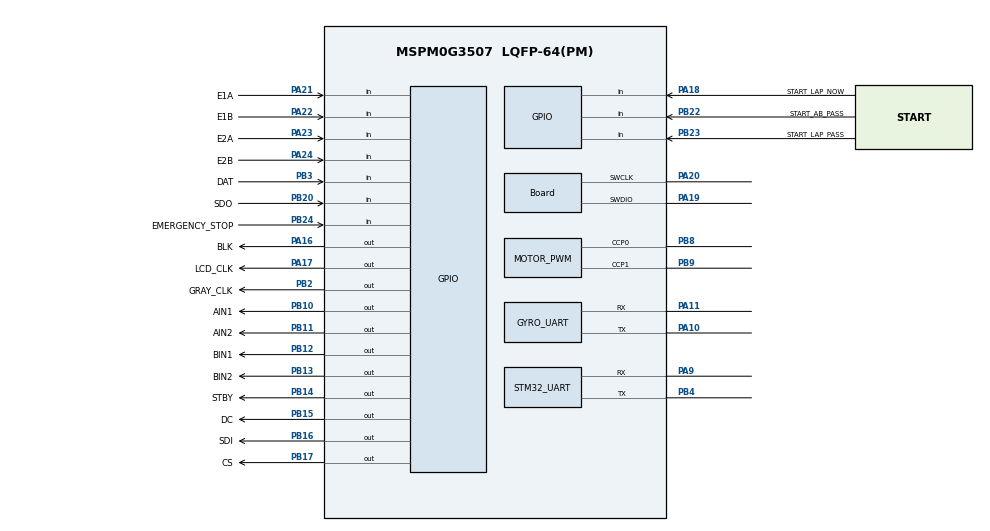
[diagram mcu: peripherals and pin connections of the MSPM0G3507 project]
/**
 * 2026 H题循迹小车 - 全新 MSPM0G3507 引脚配置
 *
 * 说明：
 * 1. 使用 MSPM0G3507 LQFP-64。
 * 2. LCD 严格按照用户给出的六根信号线配置为 GPIO 软件 SPI。
 * 3. 两路电机 PWM 共用 TIMA0，频率一致，上电占空比为 0%。
 * 4. PA19/PA20 固定保留给 SWD 调试。
 */
//@cliArgs --device "MSPM0G350X" --package "LQFP-64(PM)" --part "Default"
//@v2CliArgs --device "MSPM0G3507" --package "LQFP-64(PM)"

const Board   = scripting.addModule("/ti/driverlib/Board");
const GPIO    = scripting.addModule("/ti/driverlib/GPIO", {}, false);
const PWM     = scripting.addModule("/ti/driverlib/PWM", {}, false);
const SYSTICK = scripting.addModule("/ti/driverlib/SYSTICK");
const SYSCTL  = scripting.addModule("/ti/driverlib/SYSCTL");
const UART    = scripting.addModule("/ti/driverlib/UART", {}, false);

const LCD_GPIO       = GPIO.addInstance();
const KEY_GPIO       = GPIO.addInstance();
const MOTOR_CTRL_GPIO = GPIO.addInstance();
const ENCODER_GPIO   = GPIO.addInstance();
const GRAY_GPIO      = GPIO.addInstance();
const MOTOR_PWM      = PWM.addInstance();
const GYRO_UART      = UART.addInstance();
const STM32_UART     = UART.addInstance();

/*
 * 保留 SWD 调试口；不要把 PA19/PA20 分配给业务外设。
 */
Board.configureUnused               = false;
Board.peripheral.$assign            = "DEBUGSS";
Board.peripheral.swdioPin.$assign   = "PA19";
Board.peripheral.swclkPin.$assign   = "PA20";

/*
 * 2.4 寸 LCD：GPIO 软件 SPI。
 * CS 上电保持高，BLK 上电关闭，CLK/SDI/D-C 上电为低。
 */
LCD_GPIO.$name = "LCD_GPIO";
LCD_GPIO.associatedPins.create(6);

LCD_GPIO.associatedPins[0].$name        = "BLK";
LCD_GPIO.associatedPins[0].initialValue = "CLEARED";
LCD_GPIO.associatedPins[0].pin.$assign  = "PA16";

LCD_GPIO.associatedPins[1].$name        = "DC";
LCD_GPIO.associatedPins[1].initialValue = "CLEARED";
LCD_GPIO.associatedPins[1].pin.$assign  = "PB15";

LCD_GPIO.associatedPins[2].$name             = "SDO";
LCD_GPIO.associatedPins[2].direction         = "INPUT";
LCD_GPIO.associatedPins[2].internalResistor  = "PULL_DOWN";
LCD_GPIO.associatedPins[2].pin.$assign       = "PB20";

LCD_GPIO.associatedPins[3].$name        = "CS";
LCD_GPIO.associatedPins[3].initialValue = "SET";
LCD_GPIO.associatedPins[3].pin.$assign  = "PB17";

LCD_GPIO.associatedPins[4].$name        = "LCD_CLK";
LCD_GPIO.associatedPins[4].initialValue = "CLEARED";
LCD_GPIO.associatedPins[4].pin.$assign  = "PA17";

LCD_GPIO.associatedPins[5].$name        = "SDI";
LCD_GPIO.associatedPins[5].initialValue = "CLEARED";
LCD_GPIO.associatedPins[5].pin.$assign  = "PB16";

/*
 * 板载按键：
 * PA18 按下为高电平；PB22/PB23/PB24 按下为低电平。
 * PA18=一圈到线即停，PB22=A到B整车通过，PB23=一圈整车通过，
 * PB24=任意时刻急停。四个按键都启用中断。
 */
KEY_GPIO.$name = "KEY_GPIO";
KEY_GPIO.associatedPins.create(4);

KEY_GPIO.associatedPins[0].$name             = "START_LAP_NOW";
KEY_GPIO.associatedPins[0].direction         = "INPUT";
KEY_GPIO.associatedPins[0].internalResistor  = "PULL_DOWN";
KEY_GPIO.associatedPins[0].interruptEn       = true;
KEY_GPIO.associatedPins[0].polarity          = "RISE";
KEY_GPIO.associatedPins[0].pin.$assign       = "PA18";

KEY_GPIO.associatedPins[1].$name             = "START_AB_PASS";
KEY_GPIO.associatedPins[1].direction         = "INPUT";
KEY_GPIO.associatedPins[1].internalResistor  = "PULL_UP";
KEY_GPIO.associatedPins[1].interruptEn       = true;
KEY_GPIO.associatedPins[1].polarity          = "FALL";
KEY_GPIO.associatedPins[1].pin.$assign       = "PB22";

KEY_GPIO.associatedPins[2].$name             = "START_LAP_PASS";
KEY_GPIO.associatedPins[2].direction         = "INPUT";
KEY_GPIO.associatedPins[2].internalResistor  = "PULL_UP";
KEY_GPIO.associatedPins[2].interruptEn       = true;
KEY_GPIO.associatedPins[2].polarity          = "FALL";
KEY_GPIO.associatedPins[2].pin.$assign       = "PB23";

KEY_GPIO.associatedPins[3].$name             = "EMERGENCY_STOP";
KEY_GPIO.associatedPins[3].direction         = "INPUT";
KEY_GPIO.associatedPins[3].internalResistor  = "PULL_UP";
KEY_GPIO.associatedPins[3].interruptEn       = true;
KEY_GPIO.associatedPins[3].polarity          = "FALL";
KEY_GPIO.associatedPins[3].pin.$assign       = "PB24";

/*
 * TB6612FNG direction and standby control. All five signals start low, so
 * both bridges are disabled before PWM is allowed to reach PWMA/PWMB.
 */
MOTOR_CTRL_GPIO.$name = "MOTOR_CTRL_GPIO";
MOTOR_CTRL_GPIO.associatedPins.create(5);

MOTOR_CTRL_GPIO.associatedPins[0].$name        = "AIN1";
MOTOR_CTRL_GPIO.associatedPins[0].initialValue = "CLEARED";
MOTOR_CTRL_GPIO.associatedPins[0].pin.$assign  = "PB10";

MOTOR_CTRL_GPIO.associatedPins[1].$name        = "AIN2";
MOTOR_CTRL_GPIO.associatedPins[1].initialValue = "CLEARED";
MOTOR_CTRL_GPIO.associatedPins[1].pin.$assign  = "PB11";

MOTOR_CTRL_GPIO.associatedPins[2].$name        = "BIN1";
MOTOR_CTRL_GPIO.associatedPins[2].initialValue = "CLEARED";
MOTOR_CTRL_GPIO.associatedPins[2].pin.$assign  = "PB12";

MOTOR_CTRL_GPIO.associatedPins[3].$name        = "BIN2";
MOTOR_CTRL_GPIO.associatedPins[3].initialValue = "CLEARED";
MOTOR_CTRL_GPIO.associatedPins[3].pin.$assign  = "PB13";

MOTOR_CTRL_GPIO.associatedPins[4].$name        = "STBY";
MOTOR_CTRL_GPIO.associatedPins[4].initialValue = "CLEARED";
MOTOR_CTRL_GPIO.associatedPins[4].pin.$assign  = "PB14";

/*
 * 两路正交编码器。四根相线均配置双边沿 GPIO 中断。
 * PA21/PA22 与 PA23/PA24 还保留了以后切到定时器捕获的可能。
 */
ENCODER_GPIO.$name = "ENCODER_GPIO";
ENCODER_GPIO.associatedPins.create(4);

ENCODER_GPIO.associatedPins[0].$name       = "E1A";
ENCODER_GPIO.associatedPins[0].direction   = "INPUT";
ENCODER_GPIO.associatedPins[0].interruptEn = true;
ENCODER_GPIO.associatedPins[0].polarity    = "RISE_FALL";
ENCODER_GPIO.associatedPins[0].pin.$assign = "PA21";

ENCODER_GPIO.associatedPins[1].$name       = "E1B";
ENCODER_GPIO.associatedPins[1].direction   = "INPUT";
ENCODER_GPIO.associatedPins[1].interruptEn = true;
ENCODER_GPIO.associatedPins[1].polarity    = "RISE_FALL";
ENCODER_GPIO.associatedPins[1].pin.$assign = "PA22";

ENCODER_GPIO.associatedPins[2].$name       = "E2A";
ENCODER_GPIO.associatedPins[2].direction   = "INPUT";
ENCODER_GPIO.associatedPins[2].interruptEn = true;
ENCODER_GPIO.associatedPins[2].polarity    = "RISE_FALL";
ENCODER_GPIO.associatedPins[2].pin.$assign = "PA23";

ENCODER_GPIO.associatedPins[3].$name       = "E2B";
ENCODER_GPIO.associatedPins[3].direction   = "INPUT";
ENCODER_GPIO.associatedPins[3].interruptEn = true;
ENCODER_GPIO.associatedPins[3].polarity    = "RISE_FALL";
ENCODER_GPIO.associatedPins[3].pin.$assign = "PA24";

/*
 * 灰度辅助板两线接口：主控输出 CLK，主控读取 DAT。
 */
GRAY_GPIO.$name = "GRAY_GPIO";
GRAY_GPIO.associatedPins.create(2);

GRAY_GPIO.associatedPins[0].$name        = "GRAY_CLK";
GRAY_GPIO.associatedPins[0].initialValue = "CLEARED";
GRAY_GPIO.associatedPins[0].pin.$assign  = "PB2";

GRAY_GPIO.associatedPins[1].$name            = "DAT";
GRAY_GPIO.associatedPins[1].direction        = "INPUT";
GRAY_GPIO.associatedPins[1].internalResistor = "PULL_DOWN";
GRAY_GPIO.associatedPins[1].pin.$assign      = "PB3";

/*
 * TB6612FNG PWM：PWMA=TIMA0_C0=PB8，PWMB=TIMA0_C1=PB9。
 * 默认 32 MHz 时钟、计数 1600，对应约 20 kHz；上电占空比均为 0%。
 */
MOTOR_PWM.$name                      = "MOTOR_PWM";
MOTOR_PWM.ccIndex                    = [0, 1];
MOTOR_PWM.timerCount                 = 1600;
MOTOR_PWM.clockDivider               = 1;
MOTOR_PWM.clockPrescale              = 1;
MOTOR_PWM.peripheral.$assign         = "TIMA0";
MOTOR_PWM.peripheral.ccp0Pin.$assign = "PB8";
MOTOR_PWM.peripheral.ccp1Pin.$assign = "PB9";
MOTOR_PWM.PWM_CHANNEL_0.$name        = "MOTOR1_PWM";
MOTOR_PWM.PWM_CHANNEL_0.dutyCycle    = 0;
MOTOR_PWM.PWM_CHANNEL_0.invert       = false;
MOTOR_PWM.PWM_CHANNEL_1.$name        = "MOTOR2_PWM";
MOTOR_PWM.PWM_CHANNEL_1.dutyCycle    = 0;
MOTOR_PWM.PWM_CHANNEL_1.invert       = false;

/*
 * 单轴陀螺仪：115200, 8-N-1。
 * 模块 TX -> PA11(UART0_RX)，模块 RX <- PA10(UART0_TX)。
 */
GYRO_UART.$name                    = "GYRO_UART";
GYRO_UART.targetBaudRate           = 115200;
GYRO_UART.enableFIFO               = true;
GYRO_UART.rxFifoThreshold          = "DL_UART_RX_FIFO_LEVEL_ONE_ENTRY";
GYRO_UART.enabledInterrupts        = ["RX"];
GYRO_UART.peripheral.$assign       = "UART0";
GYRO_UART.peripheral.txPin.$assign = "PA10";
GYRO_UART.peripheral.rxPin.$assign = "PA11";

/*
 * 预留给 STM32：115200, 8-N-1，位于开发板 P6 串口座。
 * MSPM0 TX(PB4) -> STM32 RX；MSPM0 RX(PA9) <- STM32 TX。
 */
STM32_UART.$name                    = "STM32_UART";
STM32_UART.targetBaudRate           = 115200;
STM32_UART.enableFIFO               = true;
STM32_UART.rxFifoThreshold          = "DL_UART_RX_FIFO_LEVEL_ONE_ENTRY";
STM32_UART.enabledInterrupts        = [];
STM32_UART.peripheral.$assign       = "UART1";
STM32_UART.peripheral.txPin.$assign = "PB4";
STM32_UART.peripheral.rxPin.$assign = "PA9";

/*
 * 使用内部默认时钟。当前阶段不依赖外部晶振，先保证配置简洁稳定。
 */
SYSTICK.period          = 32000;
SYSTICK.periodEnable    = true;
SYSTICK.systickEnable   = true;
SYSTICK.interruptEnable = true;

SYSCTL.forceDefaultClkConfig = true;
SYSCTL.clockTreeEn           = true;
